# STM32G563 register map
File version: 2.0.0
CPU: CM33 r0p4, little endian, MPU, FPU, 4 interrupt priority bits
Registers are 32-bit, read-write, reset 0x0 unless marked. A register's access mark holds for its fields unless they carry their own. Offsets are from the block's base; [hi:lo] are bit positions; {n}, {i} and the like mark numbered series.

## OPAMP1 — OPAMP register block
Base 0x44005C00
Same registers: OPAMP2 0x44006000, OPAMP3 0x44006400, OPAMP1_S 0x54005C00, OPAMP2_S 0x54006000, OPAMP3_S 0x54006400
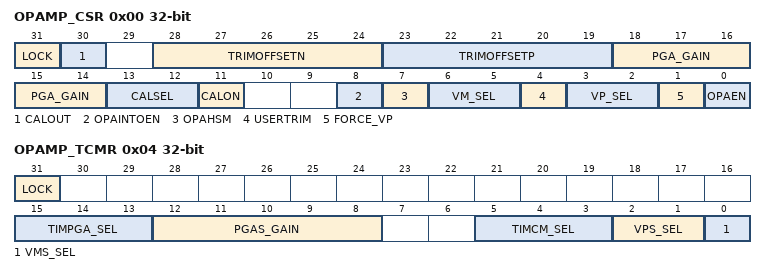
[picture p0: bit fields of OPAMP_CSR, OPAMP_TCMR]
0x00 OPAMP_CSR (reset mask 0xFFFF) — OPAMP control/status register
  [31] LOCK — OPAMP_CSR register lock
    0=OPAMP_CSR is read-write; 1=OPAMP_CSR is read-only
  [30] CALOUT ro — Operational amplifier calibration output
  [28:24] TRIMOFFSETN — Trim for NMOS differential pairs
  [23:19] TRIMOFFSETP — Trim for PMOS differential pairs
  [18:14] PGA_GAIN — Operational amplifier programmable gain and PGA flavor primary control
    0=gain 2; 1=gain 4; 2=gain 8; 3=gain 16; 8=gain -1 / gain 2 with bias on OPAMP_VINM0; 9=gain -3 / gain 4 with bias on OPAMP_VINM0; 10=gain -7 / gain 8 with bias on OPAMP_VINM0; 11=gain -15 / gain 16 with bias on OPAMP_VINM0; 16=gain 2 with filtering on OPAMP_VINM0; 17=gain 4 with filtering on OPAMP_VINM0; 18=gain 8 with filtering on OPAMP_VINM0; 19=gain 16 with filtering on OPAMP_VINM0; 24=gain -1 / gain 2 with bias on OPAMP_VINM0 and filtering on OPAMP_VINM1; 25=gain -3 / gain 4 with bias on OPAMP_VINM0 and filtering on OPAMP_VINM1; 26=gain -7 / gain 8 with bias on OPAMP_VINM0 and filtering on OPAMP_VINM1; 27=gain -15 / gain 16 with bias on OPAMP_VINM0 and filtering on OPAMP_VINM1
  [13:12] CALSEL — Calibration selection
    0=0.033*VDDA; 1=0.1*VDDA (for PMOS calibration); 2=0.5*VDDA; 3=0.9*VDDA (for NMOS calibration)
  [11] CALON — Calibration mode enable
    0=Calibration mode disabled; 1=Calibration mode enabled
  [8] OPAINTOEN — Operational amplifier internal output enable
    0=OPAMP_VOUT pin; 1=ADC/COMP channel
  [7] OPAHSM — Operational amplifier high-speed mode
    0=Normal speed; 1=High speed
  [6:5] VM_SEL — Inverting input primary selection
    0=OPAMP_VINM0 pin; 1=OPAMP_VINM1 pin; 2=Internal resistor divider middle point; 3=Operational amplifier output
  [4] USERTRIM — User trimming enable
    0=Disable (trimming by user not possible); 1=Enable (trimming by user possible)
  [3:2] VP_SEL — Noninverting input primary selection
    0=OPAMP_VINP0 pin; 1=OPAMP_VINP1 pin; 2=OPAMP_VINP2 pin; 3=OPAMP_VINP3 pin or DAC output channel
  [1] FORCE_VP — Force internal reference on noninverting input
    0=Do not force (normal operation); 1=Force
  [0] OPAEN — Operational amplifier enable
    0=Disable; 1=Enable
0x04 OPAMP_TCMR — OPAMP timer-controlled mode register
  [31] LOCK — OPAMP_TCMR register lock
    0=Read-write; 1=Read-only (OPAMP_TCMR locked)
  [15:13] TIMPGA_SEL — Timer toggle signal selection for programmable gain control
    0=None (gain permanently controlled through PGA_GAIN[4:0] and VM_SEL[1:0]); {v}=opamp_tp{v} (v=1..7)
  [12:8] PGAS_GAIN — Operational amplifier programmable gain and PGA flavor secondary control
    0=gain 2; 1=gain 4; 2=gain 8; 3=gain 16; 8=gain -1 / gain 2 with bias on OPAMP_VINM0; 9=gain -3 / gain 4 with bias on OPAMP_VINM0; 10=gain -7 / gain 8 with bias on OPAMP_VINM0; 11=gain -15 / gain 16 with bias on OPAMP_VINM0; 16=gain 2 with filtering on OPAMP_VINM0; 17=gain 4 with filtering on OPAMP_VINM0; 18=gain 8 with filtering on OPAMP_VINM0; 19=gain 16 with filtering on OPAMP_VINM0; 24=gain -1 / gain 2 with bias on OPAMP_VINM0 and filtering on OPAMP_VINM1; 25=gain -3 / gain 4 with bias on OPAMP_VINM0 and filtering on OPAMP_VINM1; 26=gain -7 / gain 8 with bias on OPAMP_VINM0 and filtering on OPAMP_VINM1; 27=gain -15 / gain of 16 with bias on OPAMP_VINM0 and filtering on OPAMP_VINM1
  [5:3] TIMCM_SEL — Timer toggle signal selection for operational amplifier input control
    0=None (input configuration permanently controlled through VP_SEL[1:0] and VM_SEL); {v}=opamp_tc{v} (v=1..7)
  [2:1] VPS_SEL — OPAMP noninverting input secondary selection.
    0=OPAMP_VINP0; 1=OPAMP_VINP1; 2=OPAMP_VINP2; 3=OPAMP_VINP3 pin or DAC output channel
  [0] VMS_SEL — OPAMP inverting input secondary selection
    0=Internal resistor divider middle point (operation as PGA); 1=Operational amplifier output (operation as follower)
